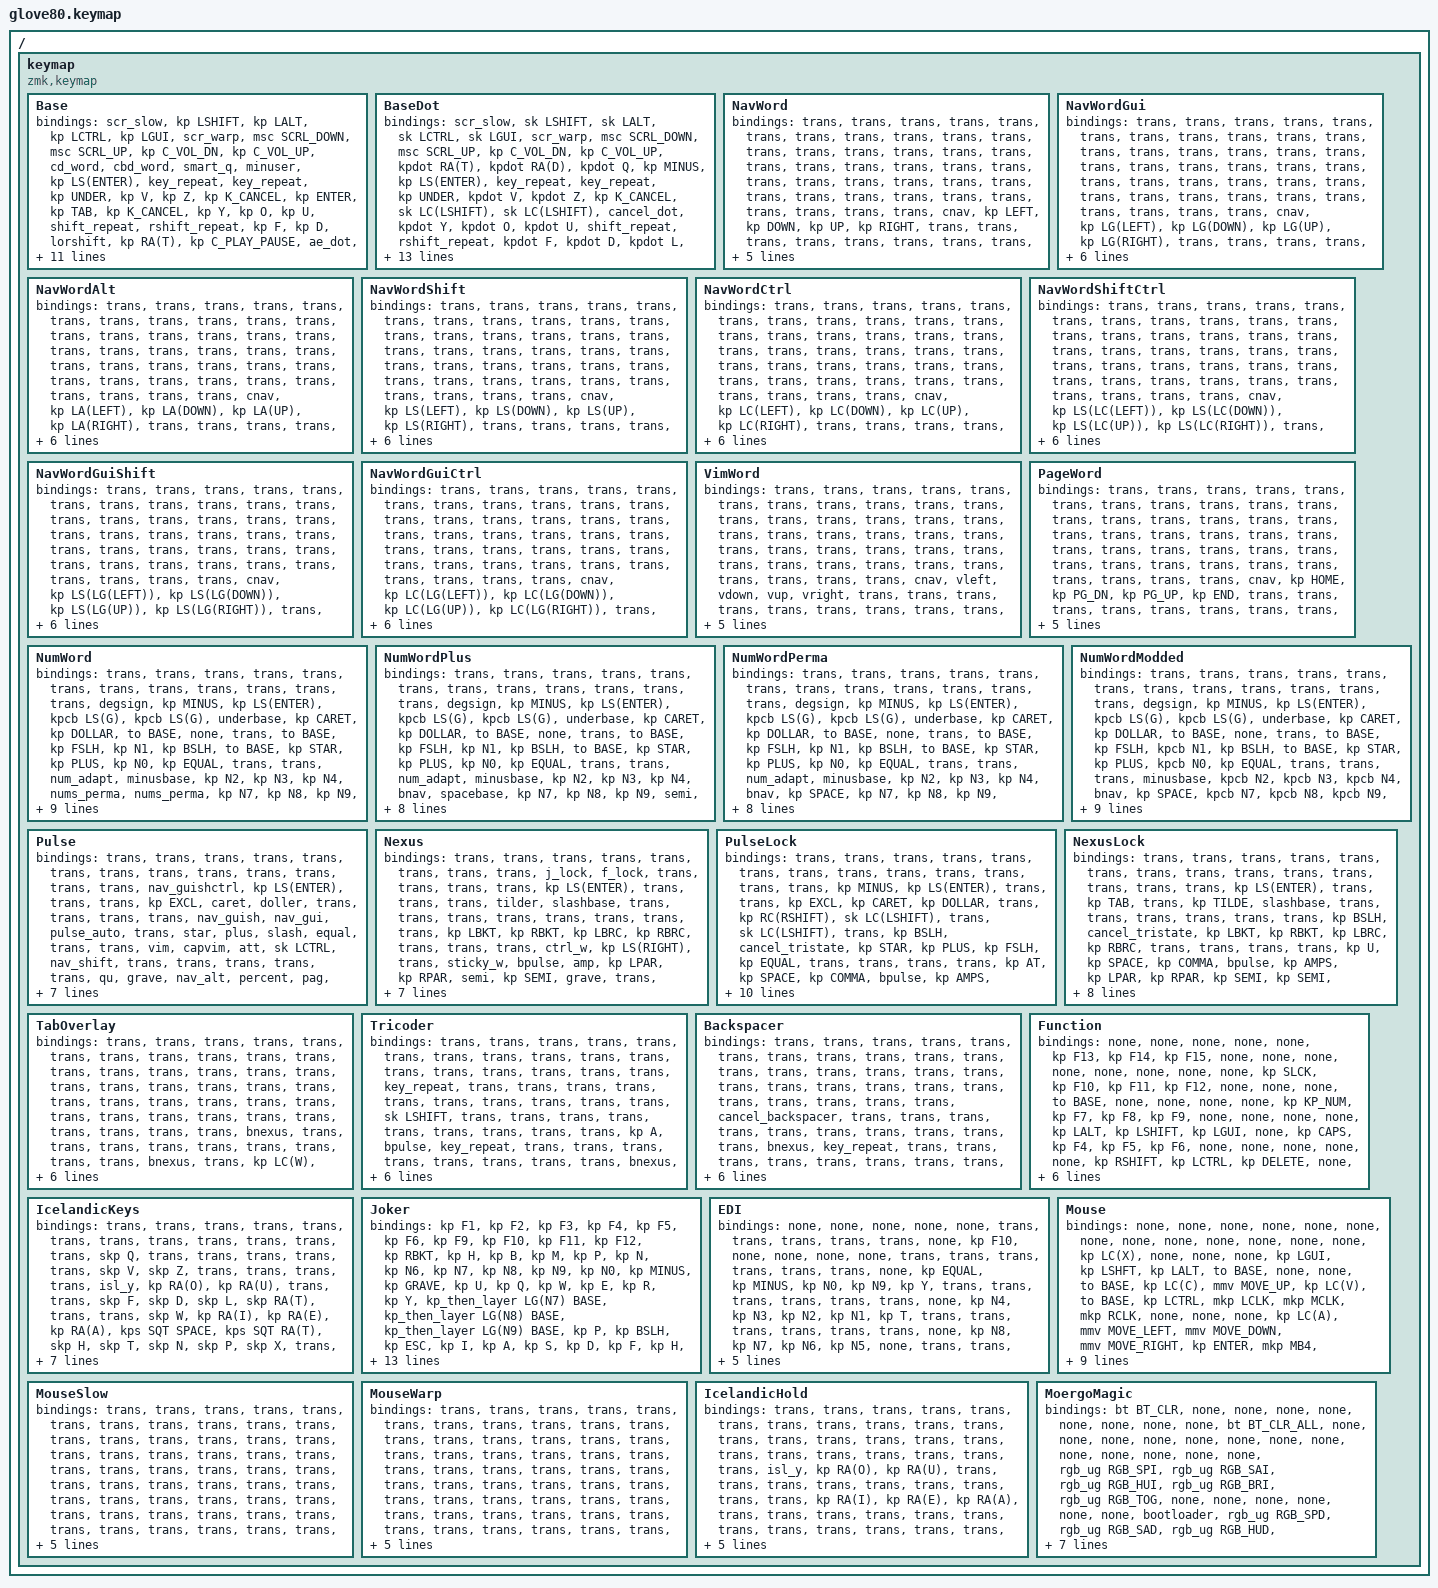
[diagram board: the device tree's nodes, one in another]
#include <behaviors.dtsi>
#include <dt-bindings/zmk/outputs.h>
#include <dt-bindings/zmk/keys.h>
#include <dt-bindings/zmk/bt.h>
#include <dt-bindings/zmk/rgb.h>
#include <behaviors/unicode.dtsi>
// Músasettings, þarf að koma á undan pointing
#define ZMK_POINTING_DEFAULT_NAVIGATION_VAL 1000// default: 600
#define ZMK_POINTING_DEFAULT_SCRL_VAL 200 // default: 10, en kveikti á smooth scrolling sem þarf mikið hærri tölur
#include <dt-bindings/zmk/input_transform.h>
#include <dt-bindings/zmk/pointing.h>
#include <input/processors.dtsi>

#define BASE 0
#define BASE_DOT 1
#define NAV_WORD 2
#define NAV_WORD_GUI 3
#define NAV_WORD_ALT 4
#define NAV_WORD_SHIFT 5
#define NAV_WORD_CTRL 6
#define NAV_WORD_SHIFT_CTRL 7
#define NAV_WORD_SHIFT_GUI 8
#define NAV_WORD_CTRL_GUI 9
#define VIM_WORD 10
#define PAGE_WORD 11
#define NUM_WORD 12
#define NUM_WORD_PLUS 13
#define NUM_WORD_PERMA 14
#define NUM_WORD_MODDED 15
#define PULSE 16
#define NEXUS 17
#define PULSE_LOCK 18
#define NEXUS_LOCK 19
#define TAB_OVERLAY 20
#define TRICODER 21
#define BACKSPACER 22
#define FUNCTIONS 23
#define ICE 24
#define JOKER 25
#define EDI_LAYER 26
#define MOUSE 27
#define MOUSE_SLOW 28
#define MOUSE_WARP 29
#define ICE_HOLD 30
#define MAGIC 31

#include "misc/glove80keys.dtsi"
#include "misc/settings.dtsi"
#include "misc/moergo.dtsi"
#include "behaviors/behaviors.dtsi"
#include "misc/combos.dtsi"
#include "misc/unicodes.dtsi"
#include "underglow.dtsi"


/ {
	keymap {
		compatible = "zmk,keymap";
		
		
		Base {
			bindings = <

			&scr_slow       &kp LSHIFT    &kp LALT   &kp LCTRL  &kp LGUI                                                                                                                            &scr_warp    &msc SCRL_DOWN &msc SCRL_UP &kp C_VOL_DN   &kp C_VOL_UP
			&cd_word        &cbd_word      &smart_q   &minuser   &kp LS(ENTER)  &key_repeat                                                                                           &key_repeat    &kp UNDER    &kp V          &kp Z        &kp K_CANCEL   &kp ENTER
			&kp TAB         &kp K_CANCEL  &kp Y      &kp O      &kp U          &shift_repeat                                                                                         &rshift_repeat &kp F        &kp D          &lorshift    &kp RA(T)      &kp C_PLAY_PAUSE
			&ae_dot         &kp W         &kp I      &kp E      &kp A          &pulse                                                                                                &thorn_eth_repeat &kp H        &kp T          &kp N        &kp P          &kp X
			&kp SQT         &ice_slmo ICE_HOLD ICE  &_dot    &sll NEXUS  &kp COMMA      &backspace     &kp UNDER    &kp K_CANCEL  &sl FUNCTIONS   &kp ESC   &kp K_CANCEL    &kp CAPS    &kp M          &kp S        &kp G          &kp B        &kp J          &kp DQT
      &magic MAGIC 0  &kp HOME      &cdeleter_enter_tab  &kp LEFT   &kp RIGHT                     &kp SPACE    &kp C         &sl NUM_WORD    &sl NUM_WORD  &kp K           &kp R                        &kp DOWN     &kp UP         &deleter_enter_tab     &kp END        &kp PSCRN
			
      >;
		};
		
		BaseDot {
			bindings = <
			
			&scr_slow        &sk LSHIFT      &sk LALT      &sk LCTRL      &sk LGUI                                                                                                                            &scr_warp    &msc SCRL_DOWN &msc SCRL_UP &kp C_VOL_DN   &kp C_VOL_UP
			&kpdot RA(T)     &kpdot RA(D)  &kpdot Q    &kp MINUS   &kp LS(ENTER)  &key_repeat                                                                                   &key_repeat    &kp UNDER  &kpdot V  &kpdot Z  &kp K_CANCEL  &sk LC(LSHIFT)
			&sk LC(LSHIFT)   &cancel_dot   &kpdot Y    &kpdot O    &kpdot U   &shift_repeat                                                                                 &rshift_repeat &kpdot F   &kpdot D  &kpdot L  &kpdot RA(T)  &kp C_PLAY_PAUSE
			&kpdot RA(P)     &kpdot W      &kpdot I    &kpdot E    &kpdot A   &pulse                                                                                        &kpdot  RA(T)  &kpdot H   &kpdot T  &kpdot N  &kpdot P      &kpdot X
			&kp SQT          &ice_slmo ICE_HOLD ICE  &kp DOT     &sll NEXUS   &kp COMMA  &backspace    &kp UNDER  &kp K_CANCEL  &sl FUNCTIONS   &nexus_auto   &kp K_CANCEL  &sk RCTRL  &kpdot M       &kpdot S   &kpdot G  &kpdot B  &kpdot J      &kpdot L
      &magic MAGIC 0   &kp HOME      &cdeleter   &kp LEFT    &kp RIGHT                &kp SPACE  &kpdot C      &sl NUM_WORD    &sl NUM_WORD  &kpdot K      &kpdot R                  &kp DOWN   &kp UP    &deleter  &kp END       &kp PSCRN
			
      >;
		};
		
		NavWord {
			bindings = <
			
			&trans  &trans  &trans    &trans  &trans                                                                         &trans     &trans     &trans     &trans  &trans
			&trans  &trans  &trans    &trans  &trans  &trans                                                       &trans    &trans     &trans     &trans     &trans  &trans
			&trans  &trans  &trans    &trans  &trans  &trans                                                       &trans    &trans     &trans     &trans     &trans  &trans
			&trans  &trans  &trans    &trans  &trans  &cnav                                                        &kp LEFT  &kp DOWN   &kp UP     &kp RIGHT  &trans  &trans
			&trans  &trans  &trans    &trans  &trans  &trans  &trans  &trans  &trans     &trans  &trans  &trans    &trans    &trans     &trans     &trans     &trans  &trans
			&trans  &trans  &trans    &trans  &trans          &trans  &trans  &trans     &trans  &trans  &trans              &trans     &trans     &trans     &trans  &trans
			
			>;
		};

		NavWordGui {
			bindings = <
			
			&trans  &trans  &trans    &trans  &trans                                                                             &trans     &trans     &trans     &trans  &trans
			&trans  &trans  &trans    &trans  &trans  &trans                                                           &trans    &trans     &trans     &trans     &trans  &trans
			&trans  &trans  &trans    &trans  &trans  &trans                                                           &trans    &trans     &trans     &trans     &trans  &trans
			&trans  &trans  &trans    &trans  &trans  &cnav                                                            &kp LG(LEFT)  &kp LG(DOWN)   &kp LG(UP)     &kp LG(RIGHT)  &trans  &trans
			&trans  &trans  &sk LGUI  &trans  &sk LGUI  &trans        &trans  &trans  &trans     &trans  &trans  &trans  &trans    &trans     &trans     &trans     &trans  &trans
			&trans  &trans  &trans    &trans  &trans                &trans  &trans  &trans     &trans  &trans  &trans          &trans     &trans     &trans     &trans  &trans
			
			>;
		};

		NavWordAlt {
			bindings = <
			
			&trans  &trans  &trans    &trans  &trans                                                                                &trans     &trans     &trans     &trans  &trans
			&trans  &trans  &trans    &trans  &trans  &trans                                                              &trans    &trans     &trans     &trans     &trans  &trans
			&trans  &trans  &trans    &trans  &trans  &trans                                                              &trans    &trans     &trans     &trans     &trans  &trans
			&trans  &trans  &trans    &trans  &trans  &cnav                                                        &kp LA(LEFT)  &kp LA(DOWN)   &kp LA(UP)     &kp LA(RIGHT)  &trans  &trans
			&trans  &trans  &trans    &trans  &trans  &trans  &trans         &trans  &trans     &trans  &trans  &trans    &trans    &trans     &trans     &trans     &trans  &trans
			&trans  &trans  &trans    &trans  &trans          &trans         &trans  &trans     &trans  &trans  &trans              &trans     &trans     &trans     &trans  &trans
			
			>;
		};

		NavWordShift {
			bindings = <
			
			&trans  &trans  &trans    &trans  &trans                                                                                &trans     &trans     &trans     &trans  &trans
			&trans  &trans  &trans    &trans  &trans  &trans                                                              &trans    &trans     &trans     &trans     &trans  &trans
			&trans  &trans  &trans    &trans  &trans  &trans                                                              &trans    &trans     &trans     &trans     &trans  &trans
			&trans  &trans  &trans    &trans  &trans  &cnav                                                               &kp LS(LEFT)  &kp LS(DOWN)   &kp LS(UP)     &kp LS(RIGHT)  &trans  &trans
			&trans  &trans  &trans    &trans  &trans  &trans  &trans         &trans  &trans     &trans  &trans  &trans    &trans    &trans     &trans     &trans     &trans  &trans
			&trans  &trans  &trans    &trans  &trans          &trans         &trans  &trans     &trans  &trans  &trans              &trans     &trans     &trans     &trans  &trans
			
			>;
		};

		NavWordCtrl {
			bindings = <
			
			&trans  &trans  &trans    &trans  &trans                                                                                &trans     &trans     &trans     &trans  &trans
			&trans  &trans  &trans    &trans  &trans  &trans                                                              &trans    &trans     &trans     &trans     &trans  &trans
			&trans  &trans  &trans    &trans  &trans  &trans                                                              &trans    &trans     &trans     &trans     &trans  &trans
			&trans  &trans  &trans    &trans  &trans  &cnav                                                               &kp LC(LEFT)  &kp LC(DOWN)   &kp LC(UP)     &kp LC(RIGHT)  &trans  &trans
			&trans  &trans  &trans    &trans  &trans  &kp LC(BACKSPACE)             &trans  &trans  &trans     &trans  &trans  &trans    &trans    &trans     &trans     &trans     &trans  &trans
			&trans  &trans  &trans    &trans  &trans                     &trans  &trans  &trans     &trans  &trans  &trans              &trans     &trans     &trans     &trans  &trans
			
			>;
		};

		NavWordShiftCtrl {
			bindings = <
			
			&trans  &trans  &trans    &trans  &trans                                                                                &trans     &trans     &trans     &trans  &trans
			&trans  &trans  &trans    &trans  &trans  &trans                                                              &trans    &trans     &trans     &trans     &trans  &trans
			&trans  &trans  &trans    &trans  &trans  &trans                                                              &trans    &trans     &trans     &trans     &trans  &trans
			&trans  &trans  &trans    &trans  &trans  &cnav                                                               &kp LS(LC(LEFT))  &kp LS(LC(DOWN))   &kp LS(LC(UP))     &kp LS(LC(RIGHT))  &trans  &cut_base
			&trans  &trans  &trans    &trans  &trans  &trans  &trans  &trans  &trans     &trans  &trans  &trans    &trans    &trans     &trans     &trans     &trans  &trans
			&trans  &trans  &trans    &trans  &trans          &trans  &copy_base  &trans &trans  &trans  &trans              &trans     &trans     &trans     &trans  &trans
			
			>;
		};

		NavWordGuiShift {
			bindings = <
			
			&trans  &trans  &trans    &trans  &trans                                                                                &trans     &trans     &trans     &trans  &trans
			&trans  &trans  &trans    &trans  &trans  &trans                                                              &trans    &trans     &trans     &trans     &trans  &trans
			&trans  &trans  &trans    &trans  &trans  &trans                                                              &trans    &trans     &trans     &trans     &trans  &trans
			&trans  &trans  &trans    &trans  &trans  &cnav                                                               &kp LS(LG(LEFT))  &kp LS(LG(DOWN))   &kp LS(LG(UP))     &kp LS(LG(RIGHT))  &trans  &trans
			&trans  &trans  &sk LGUI  &trans  &sk LGUI  &trans  &trans         &trans  &trans     &trans  &trans  &trans    &trans    &trans     &trans     &trans     &trans  &trans
			&trans  &trans  &trans    &trans  &trans          &trans         &trans  &trans     &trans  &trans  &trans              &trans     &trans     &trans     &trans  &trans
			
			>;
		};

		NavWordGuiCtrl {
			bindings = <
			
			&trans  &trans  &trans    &trans  &trans                                                                                &trans     &trans     &trans     &trans  &trans
			&trans  &trans  &trans    &trans  &trans  &trans                                                              &trans    &trans     &trans     &trans     &trans  &trans
			&trans  &trans  &trans    &trans  &trans  &trans                                                              &trans    &trans     &trans     &trans     &trans  &trans
			&trans  &trans  &trans    &trans  &trans  &cnav                                                               &kp LC(LG(LEFT))  &kp LC(LG(DOWN))   &kp LC(LG(UP))     &kp LC(LG(RIGHT))  &trans  &trans
			&trans  &trans  &trans    &trans  &trans  &trans  &trans         &trans  &trans     &trans  &trans  &trans    &trans    &trans     &trans     &trans     &trans  &trans
			&trans  &trans  &trans    &trans  &trans          &trans         &trans  &trans     &trans  &trans  &trans              &trans     &trans     &trans     &trans  &trans
			
			>;
		};

		VimWord {
			bindings = <
			
			&trans  &trans  &trans    &trans  &trans                                                                         &trans     &trans     &trans     &trans  &trans
			&trans  &trans  &trans    &trans  &trans  &trans                                                       &trans    &trans     &trans     &trans     &trans  &trans
			&trans  &trans  &trans    &trans  &trans  &trans                                                       &trans    &trans     &trans     &trans     &trans  &trans
			&trans  &trans  &trans    &trans  &trans  &cnav                                                        &vleft    &vdown     &vup       &vright    &trans  &trans
			&trans  &trans  &trans    &trans  &trans  &trans  &trans  &trans  &trans     &trans  &trans  &trans    &trans    &trans     &trans     &trans     &trans  &trans
      &trans  &hhome  &trans    &hleft  &hright         &trans  &trans  &trans     &trans  &trans  &trans              &hdown     &hup       &trans     &hend   &trans
			
			>;
		};

		PageWord {
			bindings = <
			
			&trans  &trans  &trans    &trans  &trans                                                                         &trans     &trans     &trans     &trans  &trans
			&trans  &trans  &trans    &trans  &trans  &trans                                                       &trans    &trans     &trans     &trans     &trans  &trans
			&trans  &trans  &trans    &trans  &trans  &trans                                                       &trans    &trans     &trans     &trans     &trans  &trans
			&trans  &trans  &trans    &trans  &trans  &cnav                                                        &kp HOME  &kp PG_DN  &kp PG_UP  &kp END    &trans  &trans
			&trans  &trans  &trans    &trans  &trans  &trans  &trans  &trans  &trans     &trans  &trans  &trans    &trans    &trans     &trans     &trans     &trans  &trans
			&trans  &trans  &trans    &trans  &trans          &trans  &trans  &trans     &trans  &trans  &trans              &trans     &trans     &trans     &trans  &trans
			
			>;
		};
		

		NumWord {
			bindings = <
			
			&trans   &trans      &trans     &trans       &trans                                                                                                  &trans     &trans      &trans     &trans     &trans
			&trans   &trans      &degsign   &kp MINUS    &kp LS(ENTER)  &kpcb LS(G)                                                                  &kpcb LS(G) &underbase &kp CARET   &kp DOLLAR &to BASE   &none 
			&trans   &to BASE    &kp FSLH   &kp N1       &kp BSLH   &to BASE                                                                         &kp STAR    &kp PLUS   &kp N0      &kp EQUAL  &trans   &trans 
			&num_adapt &minusbase  &kp N2     &kp N3       &kp N4     &nums_perma                                                                      &nums_perma &kp N7     &kp N8      &kp N9     &kp SEMI   &trans
			&kp SQT  &kp PRCNT   &_dot      &numnex      &_comma    &nums_plus     &kp UNDER   &to BASE &none       &none      &to BASE  &kp ENTER   &nums_plus  &kp LT     &kp GT      &kp HASH   &kp EQUAL   &kp DQT 
			&none    &nsk LCTRL  &nsk LALT  &nsk LSHIFT  &nsk LGUI                 &spacebase  &kp N5   &kp SPACE   &kp SPACE  &kp N6    &kp COLON               &nsk RGUI  &nsk RSHIFT &nsk LALT  &nsk LCTRL &kp AT 
			
			>;
		};


		NumWordPlus {
			bindings = <
			
			&trans   &trans     &trans     &trans     &trans                                                                                                   &trans     &trans     &trans     &trans    &trans
			&trans   &trans     &degsign   &kp MINUS  &kp LS(ENTER)  &kpcb LS(G)                                                                  &kpcb LS(G)  &underbase &kp CARET  &kp DOLLAR &to BASE  &none 
			&trans   &to BASE   &kp FSLH   &kp N1     &kp BSLH   &to BASE                                                                         &kp STAR     &kp PLUS   &kp N0     &kp EQUAL  &trans    &trans 
			&num_adapt  &minusbase &kp N2     &kp N3     &kp N4     &bnav                                                                            &spacebase   &kp N7     &kp N8     &kp N9     &semi     &trans
			&kp SQT  &kp PRCNT  &_dot      &sll NEXUS  &_comma    &kp BACKSPACE   &kp UNDER   &to BASE &none       &none      &to BASE  &kp ENTER  &to BASE     &kp LT     &kp GT     &kp HASH   &kp EQUAL &kp DQT
			&none    &kp HOME   &none      &kp LEFT   &kp RIGHT                  &spacebase  &kp N5   &kp SPACE   &kp SPACE  &kp N6   &kp COLON                &downbase  &upbase    &kp AT     &kp END   &none 
			
			>;
		};

		NumWordPerma {
			bindings = <
			
			&trans   &trans     &trans     &trans     &trans                                                                                                   &trans     &trans     &trans     &trans    &trans
			&trans   &trans     &degsign   &kp MINUS  &kp LS(ENTER)  &kpcb LS(G)                                                                  &kpcb LS(G)  &underbase  &kp CARET  &kp DOLLAR &to BASE  &none 
			&trans   &to BASE   &kp FSLH   &kp N1     &kp BSLH   &to BASE                                                                         &kp STAR     &kp PLUS   &kp N0     &kp EQUAL  &trans    &trans 
			&num_adapt   &minusbase &kp N2     &kp N3     &kp N4     &bnav                                                                            &kp SPACE    &kp N7     &kp N8     &kp N9     &kp SEMI  &trans
			&kp SQT  &kp PRCNT  &_dot      &sll NEXUS  &_comma    &kp BACKSPACE   &kp UNDER  &to BASE &none       &none      &to BASE  &kp ENTER   &to BASE     &kp LT     &kp GT     &kp HASH   &kp EQUAL &kp DQT
			&none    &kp HOME   &none      &kp LEFT   &kp RIGHT                  &kp SPACE  &kp N5   &kp SPACE   &kp SPACE  &kp N6   &kp COLON                &downbase  &upbase    &kp AT     &kp END   &none 
			
			>;
		};

		NumWordModded {
			bindings = <
			
			&trans   &trans      &trans     &trans      &trans                                                                                                  &trans     &trans      &trans     &trans     &trans
			&trans   &trans      &degsign   &kp MINUS   &kp LS(ENTER) &kpcb LS(G)                                                                  &kpcb LS(G)  &underbase &kp CARET   &kp DOLLAR &to BASE   &none 
			&trans   &to BASE    &kp FSLH   &kpcb N1    &kp BSLH  &to BASE                                                                         &kp STAR     &kp PLUS   &kpcb N0    &kp EQUAL  &trans     &trans 
			&trans   &minusbase  &kpcb N2   &kpcb N3    &kpcb N4  &bnav                                                                            &kp SPACE    &kpcb N7   &kpcb N8    &kpcb N9   &kp SEMI   &none
			&kp SQT  &kp PRCNT   &_dot      &sll NEXUS   &_comma   &kp BACKSPACE   &kp UNDER   &to BASE &none       &none      &to BASE  &kp ENTER  &to BASE     &kp LT     &kp GT      &kp HASH   &kp EQUAL   &kp DQT
			&none    &nsk LCTRL  &nsk LALT  &nsk LSHIFT &nsk LGUI                 &spacebase  &kpcb N5 &kp SPACE   &kp SPACE  &kpcb N6  &kp COLON               &nsk RGUI  &nsk RSHIFT &nsk LALT  &nsk LCTRL &kp AT 
			
			>;
		};

		Pulse {
			bindings = <
			
			&trans   &trans   &trans    &trans     &trans                                                                                                &trans     &trans      &trans    &trans  &trans
			&trans   &trans   &trans    &nav_guishctrl     &kp LS(ENTER) &trans                                                                         &trans   &kp EXCL   &caret      &doller   &trans  &trans
			&trans   &trans   &nav_guish &nav_gui &pulse_auto  &trans                                                                         &star    &plus      &slash      &equal    &trans  &trans
			&vim     &capvim  &att      &sk LCTRL   &nav_shift    &trans                                                                         &trans   &trans     &trans      &trans    &qu     &grave
			&nav_alt &percent &pag      &sll NEXUS  &enters       &ctrl_w  &trans &nav_ctrlshift_macro &trans    &trans      &trans    &cbd_word  &bslash  &less      &greater    &hash     &trans  &trans
			&trans   &trans   &trans    &trans     &trans                &nav_guictrl &nav_ctrl &bnums_perma   &bnums_perma &coolword &colon             &ctrl_tab  &sctrl_tab  &trans    &trans  &trans
		
			>;
		};

		Nexus {
			bindings = <
			
			&trans  &trans   &trans      &trans     &trans                                                                                                   &trans    &trans    &trans    &j_lock  &f_lock
			&trans  &trans   &trans      &trans     &kp LS(ENTER) &trans                                                                           &trans    &trans    &tilder   &slashbase  &trans   &trans
			&trans  &trans   &trans      &trans     &trans    &trans                                                                               &kp LBKT  &kp RBKT  &kp LBRC  &kp RBRC  &trans   &trans
			&trans  &ctrl_w  &kp LS(RIGHT) &trans   &sticky_w &bpulse                                                                              &amp      &kp LPAR  &kp RPAR  &semi     &kp SEMI &grave
			&trans  &numnex  &nexus_auto &sll NEXUS  &enters   &tabber  &kp UNDER  &trans     &trans         &trans       &trans     &cd_word       &mouse    &qmark    &exclaim  &pipe     &trans   &trans
			&trans  &trans   &trans      &trans     &trans             &kp SPACE  &sk LCTRL  &bnums_perma   &bnums_perma  &kp INSERT  &sl FUNCTIONS          &gui_tab  &sgui_tab &trans    &trans   &trans

			>;
		};

		PulseLock {
			bindings = <
			
			&trans    &trans   &trans    &trans     &trans                                                                                          &trans     &trans      &trans    &trans  &trans
			&trans         &trans    &trans    &kp MINUS   &kp LS(ENTER)  &trans                                                                              &trans       &kp EXCL   &kp CARET  &kp DOLLAR  &trans     &kp RC(RSHIFT)
			&sk LC(LSHIFT) &trans    &sk LC(LSHIFT) &trans &kp BSLH   &cancel_tristate                                                                    &kp STAR     &kp PLUS   &kp FSLH   &kp EQUAL   &trans     &trans
			&trans         &trans    &kp AT    &kp SPACE   &kp COMMA  &bpulse                                                                             &kp AMPS     &kp LPAR   &kp RPAR   &kp SEMI    &bnums_perma &kp GRAVE
			&trans         &kp PRCNT &kp DOT   &sll NEXUS   &enters    &kp BACKSPACE  &trans &nav_ctrlshift_macro &trans  &trans       &trans    &trans    &cancel_tristate &kp LT     &kp GT     &kp HASH    &kp EQUAL  &trans
			&trans         &trans    &sk LGUI  &leftbase   &rightbase                &kp SPACE &sk LCTRL    &bnums_perma &bnums_perma &coolword &kp COLON              &kp DOWN   &kp UP     &trans      &trans     &trans
		
			>;
		};

    /* (næstum) hreint afrit af Nexus, þurfti það (af illskiljanlegum ástæðum) til að láta nexus_auto virka */
    /* nema ókei leysum upp úr tristates, annað veldur veseni í vissum aðstæðum td ? -> enter -> nexus */
		NexusLock {
			bindings = <
			
			&trans    &trans   &trans    &trans     &trans                                                                                                   &trans     &trans      &trans    &trans  &trans
			&trans  &trans     &trans    &trans     &kp LS(ENTER)  &trans                                                                          &kp TAB   &trans     &kp TILDE  &slashbase &trans   &trans
			&trans  &trans     &trans    &trans     &kp BSLH   &cancel_tristate                                                                    &kp LBKT  &kp RBKT   &kp LBRC   &kp RBRC   &trans &trans
			&trans  &trans     &kp U     &kp SPACE  &kp COMMA  &bpulse                                                                             &kp AMPS  &kp LPAR   &kp RPAR   &kp SEMI   &kp SEMI &kp GRAVE
			&trans  &kp AT     &kp DOT   &sll NEXUS  &enters    &kp BACKSPACE  &kp UNDER  &trans     &trans        &trans       &trans     &trans   &cancel_tristate  &kp QMARK  &kp EXCL   &kp PIPE   &trans   &trans
			&trans  &trans     &trans    &leftbase  &rightbase               &kp SPACE  &sk LCTRL  &bnums_perma   &bnums_perma &coolword  &kp COLON          &kp DOWN   &kp UP     &trans     &trans   &trans
			
			>;
		};

		TabOverlay {
			bindings = <
			
			&trans  &trans  &trans  &trans  &trans                                                                  &trans  &trans  &trans  &trans  &trans
			&trans  &trans  &trans  &trans  &trans  &trans                                                  &trans  &trans  &trans  &trans  &trans  &trans
			&trans  &trans  &trans  &trans  &trans  &trans                                                  &trans  &trans  &trans  &trans  &trans  &trans
			&trans  &trans  &trans  &trans  &trans  &bnexus                                               &trans  &trans  &trans  &trans  &trans  &trans
			&trans  &trans  &trans  &bnexus &trans  &kp LC(W)             &trans  &trans  &trans  &trans  &trans  &trans  &trans  &trans  &trans  &trans  &trans  &trans
			&trans  &trans  &trans  &kp LC(LS(PG_UP))  &kp LC(LS(PG_DN))   &trans  &trans  &trans  &trans  &trans  &trans          &kp LC(TAB)  &kp LC(LS(TAB))  &trans  &trans  &trans
			
			>;
		};

		Tricoder {
			bindings = <
			
			&trans  &trans  &trans  &trans  &trans                                                                                               &trans       &trans  &trans  &trans  &trans
			&trans  &trans  &trans  &trans  &trans    &trans                                                                        &trans       &key_repeat  &trans  &trans  &trans  &trans
			&trans  &trans  &trans  &trans  &trans    &trans                                                                        &sk LSHIFT   &trans       &trans  &trans  &trans  &trans
			&trans  &trans  &trans  &trans  &kp A     &bpulse                                                                       &key_repeat  &trans       &trans  &trans  &trans  &trans
			&trans  &trans  &trans  &bnexus &kp ENTER &kp BACKSPACE &trans  &trans  &trans        &trans      &trans  &trans        &kp ESC      &trans       &trans  &trans  &trans  &trans
			&trans  &trans  &kp TAB &trans   &trans                  &trans   &trans  &bnums_plus  &bnums_plus &kp LS(ENTER)  &trans              &trans       &trans  &kp TAB  &trans &trans
			
			>;
		};

		Backspacer {
			bindings = <
			
			&trans  &trans  &trans  &trans  &trans                                                                  &trans  &trans  &trans  &trans  &trans
			&trans  &trans  &trans  &trans  &trans  &trans                                                  &trans  &trans  &trans  &trans  &trans  &trans
			&trans  &trans  &trans  &trans  &trans  &trans                                                  &cancel_backspacer      &trans  &trans  &trans  &trans  &trans
			&trans  &trans  &trans  &trans  &trans  &bnexus                                               &key_repeat  &trans  &trans  &trans  &trans  &trans
			&trans  &trans  &trans  &bnexus &trans  &kp LC(BACKSPACE)   &trans  &trans  &trans  &trans  &trans  &trans  &trans  &trans  &trans  &trans  &trans  &trans
			&trans  &trans  &trans  &trans  &trans                      &trans  &trans  &trans  &trans  &trans  &trans          &trans  &trans  &trans  &trans  &trans
			
			>;
		};

		Function {
			bindings = <
			
			&none  &none  &none     &none      &none                                                                                            &kp F13  &kp F14  &kp F15  &none  &none
			&none  &none  &none     &none      &none     &none                                                                      &kp SLCK    &kp F10  &kp F11  &kp F12  &none  &none
			&none  &to BASE &none   &none      &none     &none                                                                      &kp KP_NUM  &kp F7   &kp F8   &kp F9   &none  &none
			&none  &none  &kp LALT  &kp LSHIFT &kp LGUI  &none                                                                      &kp CAPS    &kp F4   &kp F5   &kp F6   &none  &none
			&none  &none  &none     &kp RSHIFT &kp LCTRL &kp DELETE &none  &to BASE &none   &kp C_BRI_DN  &to BASE      &kp C_BRI_UP   &to BASE    &kp F1   &kp F2   &kp F3   &none  &none
			&none  &none  &kp LC(DELETE)     &none      &none             &none  &none  &none     &kp C_MUTE    &volume_down  &volume_up                 &kp C_PREV    &kp C_NEXT    &kp DELETE    &none  &to JOKER
			
			>;
		};
		
		IcelandicKeys {
			bindings = <
			
			&trans  &trans  &trans       &trans       &trans                                                                                  &trans  &trans  &trans  &trans  &trans
			&trans  &trans  &skp Q       &trans       &trans       &trans                                                     &trans          &trans  &skp V  &skp Z  &trans  &trans
			&trans  &trans  &isl_y       &kp RA(O)    &kp RA(U)    &trans                                                     &trans          &skp F  &skp D  &skp L  &skp RA(T)  &trans
			&trans  &skp W  &kp RA(I)    &kp RA(E)    &kp RA(A)    &kps SQT SPACE                                               &kps SQT RA(T)  &skp H  &skp T  &skp N  &skp P  &skp X
			&trans  &trans  &kps SQT DOT &kps SQT SQT &kps SQT COMMA &trans &trans &trans  &trans  &trans  &trans  &trans  &skp M          &skp S  &skp G  &skp B  &skp J  &skp J
			&trans  &trans  &trans       &trans       &trans                &kps SQT SPACE &skp C  &trans    &trans  &skp K  &skp R                  &trans  &trans  &trans  &trans  &trans
			
			>;
		};
		
		Joker {
			bindings = <
			
			&kp F1     &kp F2    &kp F3  &kp F4  &kp F5                                                                                          &kp F6                      &kp F9                      &kp F10                     &kp F11   &kp F12
			&kp RBKT   &kp H     &kp B   &kp M   &kp P   &kp N                                                                           &kp N6  &kp N7                      &kp N8                      &kp N9                      &kp N0    &kp MINUS
			&kp GRAVE  &kp U     &kp Q   &kp W   &kp E   &kp R                                                                           &kp Y   &kp_then_layer LG(N7) BASE  &kp_then_layer LG(N8) BASE  &kp_then_layer LG(N9) BASE  &kp P     &kp BSLH
			&kp ESC    &kp I     &kp A   &kp S   &kp D   &kp F                                                                           &kp H   &kp_then_layer LG(N4) BASE  &kp_then_layer LG(N5) BASE  &kp_then_layer LG(N6) BASE  &kp SEMI  &kp SQT
			&kp TAB    &kp Z     &kp X   &kp G   &kp C   &kp V  &kp LSHFT  &kp LCTRL  &kp LALT     &kp LALT  &kp RCTRL     &kp RSHFT     &kp N   &kp_then_layer LG(N1) BASE  &kp_then_layer LG(N2) BASE  &kp_then_layer LG(N3) BASE  &kp FSLH  &kp DEL
			&kp PSCRN  &kp BSPC  &kp J   &kp K   &kp T          &mo EDI_LAYER    &kp SPACE  &kp RET      &kp RGUI  &kp C_VOL_DN  &kp C_VOL_UP          &kp UP                      &kp DOWN                    &kp LBKT                    &kp RBKT  &to 0
			
			>;
		};
		
		EDI {
			bindings = <
			
			&none  &none      &none      &none   &none                                                                       &trans  &trans  &trans  &trans  &trans
			&none  &kp F10    &none      &none   &none     &none                                                     &trans  &trans  &trans  &trans  &trans  &trans
			&none  &kp EQUAL  &kp MINUS  &kp N0  &kp N9    &kp Y                                                     &trans  &trans  &trans  &trans  &trans  &trans
			&none  &kp N4     &kp N3     &kp N2  &kp N1    &kp T                                                     &trans  &trans  &trans  &trans  &trans  &trans
			&none  &kp N8     &kp N7     &kp N6  &kp N5    &none  &trans  &trans  &trans     &trans  &trans  &trans  &trans  &trans  &trans  &trans  &trans  &trans
			&none  &kp LEFT   &kp DOWN   &kp UP  &kp RIGHT        &trans  &trans  &trans     &trans  &trans  &trans          &trans  &trans  &trans  &trans   &to 0
			
			>;
		};
		
		Mouse {
			bindings = <
			
			&none  &none      &none           &none           &none                                                                                                                      &none           &none           &none           &none     &none
			&none  &none      &none           &kp LC(X)       &none            &none                                                                                          &none      &kp LGUI        &kp LSHFT       &kp LALT           &to BASE     &none
			&none  &to BASE   &kp LC(C)       &mmv MOVE_UP    &kp LC(V)        &to BASE                                                                                       &kp LCTRL  &mkp LCLK       &mkp MCLK       &mkp RCLK       &none     &none
			&none  &kp LC(A)  &mmv MOVE_LEFT  &mmv MOVE_DOWN  &mmv MOVE_RIGHT  &kp ENTER                                                                                      &mkp MB4   &mouse_fast_hold  &mo MOUSE_WARP  &mo MOUSE_SLOW  &mkp MB5  &none
			&none  &none      &none           &none           &kp LS(ENTER)    &kp BACKSPACE  &msc SCRL_LEFT  &to BASE      &msc SCRL_RIGHT    &none      &to BASE   &mkp MCLK    &to BASE   &none           &none           &none           &none     &none
			&none  &none      &none           &none           &kp TAB                         &msc SCRL_DOWN  &msc SCRL_UP  &none              &none      &mkp RCLK  &mkp LCLK               &kp LC(TAB)     &kp LC(LS(TAB)) &none           &none     &none
			
			>;
		};
		
		MouseSlow {
			bindings = <
			
			&trans  &trans  &trans  &trans  &trans                                                                  &trans  &trans  &trans  &trans  &trans
			&trans  &trans  &trans  &trans  &trans  &trans                                                  &trans  &trans  &trans  &trans  &trans  &trans
			&trans  &trans  &trans  &trans  &trans  &trans                                                  &trans  &trans  &trans  &trans  &trans  &trans
			&trans  &trans  &trans  &trans  &trans  &trans                                                  &trans  &trans  &trans  &trans  &trans  &trans
			&trans  &trans  &trans  &trans  &trans  &trans  &trans  &trans  &trans  &trans  &trans  &trans  &trans  &trans  &trans  &trans  &trans  &trans
			&trans  &trans  &trans  &trans  &trans          &trans  &trans  &trans  &trans  &trans  &trans          &trans  &trans  &trans  &trans  &trans
			
			>;
		};
		
		MouseWarp {
			bindings = <
			
			&trans  &trans  &trans  &trans  &trans                                                                  &trans  &trans  &trans  &trans  &trans
			&trans  &trans  &trans  &trans  &trans  &trans                                                  &trans  &trans  &trans  &trans  &trans  &trans
			&trans  &trans  &trans  &trans  &trans  &trans                                                  &trans  &trans  &trans  &trans  &trans  &trans
			&trans  &trans  &trans  &trans  &trans  &trans                                                  &trans  &trans  &trans  &trans  &trans  &trans
			&trans  &trans  &trans  &trans  &trans  &trans  &trans  &trans  &trans  &trans  &trans  &trans  &trans  &trans  &trans  &trans  &trans  &trans
			&trans  &trans  &trans  &trans  &trans          &trans  &trans  &trans  &trans  &trans  &trans          &trans  &trans  &trans  &trans  &trans
			
			>;
		};
		
		IcelandicHold {
			bindings = <
			
			&trans  &trans  &trans  &trans  &trans                                                                  &trans  &trans  &trans  &trans  &trans
			&trans  &trans  &trans  &trans  &trans  &trans                                                  &trans  &trans  &trans  &trans  &trans  &trans
			&trans  &trans  &isl_y  &kp RA(O)  &kp RA(U)  &trans                                            &trans  &trans  &trans  &trans  &trans  &trans
			&trans  &trans  &kp RA(I)  &kp RA(E)  &kp RA(A)  &trans                                         &trans  &trans  &trans  &trans  &trans  &trans
			&trans  &trans  &trans  &trans  &trans  &trans  &trans  &trans  &trans  &trans  &trans  &trans  &trans  &trans  &trans  &trans  &trans  &trans
			&trans  &trans  &trans  &trans  &trans          &trans  &trans  &trans  &trans  &trans  &trans          &trans  &trans  &trans  &trans  &trans
			
			>;
		};

		/* MouseSwitcher { */
		/* 	bindings = < */
		/**/
		/* 	&none      &none       &none      &none        &none                                                                         &none      &none        &none      &none      &none  */
		/* 	&none      &none       &none      &none        &none   &none                                                         &none   &none      &none        &none      &none      &none  */
		/* 	&none      &none       &none      &kpm LG(N1)   &none   &none                                                         &none   &none      &kpm LG(N0)       &none      &none      &none  */
		/* 	&none      &none       &kpm LG(N2) &kpm LG(N3)   &kpm LG(N4)  &none                                                         &none   &kpm LG(N7)     &kpm LG(N8)       &kpm LG(N9)     &none      &none  */
		/* 	&none      &none       &none      &none        &none   &none     &none   &none   &none       &none   &none   &kpm LG(R)   &none   &none      &none       &none      &none      &none  */
		/* 	&none      &none       &none      &none        &none             &none   &kpm LG(N5)  &none       &none   &kpm LG(N6)  &none           &none      &none        &none      &none      &none  */
		/**/
		/* 	>; */
		/* }; */

		/* UnicodeLayer { */
		/* 	bindings = < */
		/**/
		/* 	&uc alien_uc        &uc ufo_uc           &uc rocket_uc          &uc magic_wand_uc   &uc wizard_uc                                                                                                                                          &uc elf_uc             &uc vampire_uc               &uc zombie_uc           &uc crystal_ball_uc &uc sparkle_uc  */
		/* 	&uc clown_uc        &uc partying_face_uc &uc joy_uc             &uc star_struck_uc  &uc heart_eyes_uc   &uc exploding_head_uc                                                                                        &spacebase            &uc smirk_uc           &uc thinking_uc              &uc scream_uc           &uc boom_uc         &uc skull_uc  */
		/* 	&uc hear_no_evil_uc &to BASE             &uc brain_uc           &uc waving_hand_uc  &kp SPACE           &sk LSHIFT                                                                                                   &sk RSHIFT            &uc fire_combo_uc      &uc dagger_uc                &uc livelong_uc         &uc metal_uc        &uc turtle_uc  */
		/* 	&uc yinyang_uc      &spacebase           &uc pinched_fingers_uc &uc euro_uc         &uc palm_up_hand_uc &enterbase                                                                                                   &uc less_combo_uc     &uc saluting_face_uc   &uc tradecopy_uc             &uc greater_combo_uc    &uc impliesiff_uc   &uc index_pointing_at_the_viewer_uc  */
		/* 	&uc star_glow_uc    &uc 0x2764 0         &uc broken_heart_uc    &kp SPACE           &uc ok_hand_uc      &kp BACKSPACE  &none   &to BASE  &kp ENTER     &kp ENTER       &to BASE         &uc two_hearts_uc  &uc permille_uc       &uc sparkling_heart_uc &uc revolving_hearts_uc      &uc tada_uc             &uc brain_uc        &uc books_uc  */
		/* 	&uc warning_uc      &uc exclamation_uc   &uc question_uc        &uc left_uc         &uc right_uc                       &spacebase &trans &uc dice_uc   &uc bullseye_uc &uc sob_skull_uc &bnexus                                  &uc down_uc            &uc up_uc      &uc underage_uc              &uc no_mobile_phones_uc &uc peace_uc  */
		/**/
		/* 	>; */
		/* }; */

		MoergoMagic {
			bindings = <
			
			&bt BT_CLR   &none            &none            &none            &none                                                                                          &none   &none   &none   &none  &bt BT_CLR_ALL
			&none        &none            &none            &none            &none            &none                                                                 &none   &none   &none   &none   &none  &none
			&none        &rgb_ug RGB_SPI  &rgb_ug RGB_SAI  &rgb_ug RGB_HUI  &rgb_ug RGB_BRI  &rgb_ug RGB_TOG                                                       &none   &none   &none   &none   &none  &none
			&bootloader  &rgb_ug RGB_SPD  &rgb_ug RGB_SAD  &rgb_ug RGB_HUD  &rgb_ug RGB_BRD  &rgb_ug RGB_EFF                                                       &none   &none   &none   &none   &none  &bootloader
			&sys_reset   &none            &none            &none            &none            &none            &bt_2   &bt_3  &none            &none  &none  &none  &none   &none   &none   &none   &none  &sys_reset
			&none        &none            &none            &none            &none                             &bt_0   &bt_1  &out OUT_USB     &none  &none  &none          &none   &none   &none   &none  &none
			
			>;
		};

	};
};
